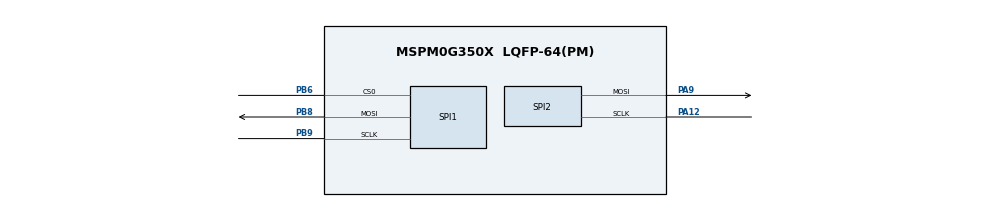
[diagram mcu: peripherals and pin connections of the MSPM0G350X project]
/**
 *
 * @cliArgs --device "MSPM0G350X" --part "Default" --package "LQFP-64(PM)" --product "mspm0_sdk@2.11.00.07"
 * @versions {"tool":"1.28.0+4696"}
 */

/**
 * Import the modules used in this configuration.
 */
const ADC12         = scripting.addModule("/ti/driverlib/ADC12", {}, false);
const ADC121        = ADC12.addInstance();
const ADC122        = ADC12.addInstance();
const Board         = scripting.addModule("/ti/driverlib/Board");
const GPIO          = scripting.addModule("/ti/driverlib/GPIO", {}, false);
const GPIO1         = GPIO.addInstance();
const GPIO2         = GPIO.addInstance();
const GPIO3         = GPIO.addInstance();
const SPI           = scripting.addModule("/ti/driverlib/SPI", {}, false);
const SPI1          = SPI.addInstance();
const SPI2          = SPI.addInstance();
const SYSCTL        = scripting.addModule("/ti/driverlib/SYSCTL");
const TIMER         = scripting.addModule("/ti/driverlib/TIMER", {}, false);
const TIMER1        = TIMER.addInstance();
const ProjectConfig = scripting.addModule("/ti/project_config/ProjectConfig");

/**
 * Write custom configuration values to the imported modules.
 */
const gate8  = system.clockTree["MFPCLKGATE"];
gate8.enable = true;

ADC121.$name                          = "SIGNAL_ADC_A";
ADC121.sampClkSrc                     = "DL_ADC12_CLOCK_ULPCLK";
ADC121.adcMem0chansel                 = "DL_ADC12_INPUT_CHAN_2";
ADC121.sampleTime0                    = "62.5ns";
ADC121.powerDownMode                  = "DL_ADC12_POWER_DOWN_MODE_MANUAL";
ADC121.trigSrc                        = "DL_ADC12_TRIG_SRC_EVENT";
ADC121.repeatMode                     = true;
ADC121.adcMem0trig                    = "DL_ADC12_TRIGGER_MODE_TRIGGER_NEXT";
ADC121.subChanID                      = 1;
ADC121.configureDMA                   = true;
ADC121.sampCnt                        = 1;
ADC121.enabledDMATriggers             = ["DL_ADC12_DMA_MEM0_RESULT_LOADED"];
ADC121.enabledInterrupts              = ["DL_ADC12_INTERRUPT_DMA_DONE"];
ADC121.peripheral.$assign             = "ADC0";
ADC121.peripheral.adcPin2.$assign     = "PA25";
ADC121.adcPin2Config.$name            = "ti_driverlib_gpio_GPIOPinGeneric0";
ADC121.DMA_CHANNEL.$name              = "SIGNAL_ADC_A_DMA";
ADC121.DMA_CHANNEL.addressMode        = "f2b";
ADC121.DMA_CHANNEL.srcLength          = "HALF_WORD";
ADC121.DMA_CHANNEL.dstLength          = "HALF_WORD";
ADC121.DMA_CHANNEL.peripheral.$assign = "DMA_CH0";

ADC122.$name                          = "SIGNAL_ADC_B";
ADC122.sampClkSrc                     = "DL_ADC12_CLOCK_ULPCLK";
ADC122.adcMem0chansel                 = "DL_ADC12_INPUT_CHAN_2";
ADC122.sampleTime0                    = "62.5ns";
ADC122.powerDownMode                  = "DL_ADC12_POWER_DOWN_MODE_MANUAL";
ADC122.trigSrc                        = "DL_ADC12_TRIG_SRC_EVENT";
ADC122.repeatMode                     = true;
ADC122.adcMem0trig                    = "DL_ADC12_TRIGGER_MODE_TRIGGER_NEXT";
ADC122.subChanID                      = 2;
ADC122.configureDMA                   = true;
ADC122.sampCnt                        = 1;
ADC122.enabledDMATriggers             = ["DL_ADC12_DMA_MEM0_RESULT_LOADED"];
ADC122.enabledInterrupts              = ["DL_ADC12_INTERRUPT_DMA_DONE"];
ADC122.peripheral.$assign             = "ADC1";
ADC122.peripheral.adcPin2.$assign     = "PA17";
ADC122.adcPin2Config.$name            = "ti_driverlib_gpio_GPIOPinGeneric1";
ADC122.DMA_CHANNEL.$name              = "SIGNAL_ADC_B_DMA";
ADC122.DMA_CHANNEL.addressMode        = "f2b";
ADC122.DMA_CHANNEL.srcLength          = "HALF_WORD";
ADC122.DMA_CHANNEL.dstLength          = "HALF_WORD";
ADC122.DMA_CHANNEL.peripheral.$assign = "DMA_CH1";

GPIO1.$name                          = "GPIO_TFT_CTRL";
GPIO1.associatedPins.create(2);
GPIO1.associatedPins[0].$name        = "TFT_DC";
GPIO1.associatedPins[0].assignedPort = "PORTB";
GPIO1.associatedPins[0].assignedPin  = "15";
GPIO1.associatedPins[1].$name        = "TFT_BLK";
GPIO1.associatedPins[1].initialValue = "SET";
GPIO1.associatedPins[1].assignedPort = "PORTB";
GPIO1.associatedPins[1].assignedPin  = "12";

GPIO2.$name                              = "GPIO_KEYPAD";
GPIO2.associatedPins.create(8);
GPIO2.associatedPins[0].$name            = "KEYPAD_R1";
GPIO2.associatedPins[0].initialValue     = "SET";
GPIO2.associatedPins[0].assignedPort     = "PORTB";
GPIO2.associatedPins[0].assignedPin      = "16";
GPIO2.associatedPins[1].$name            = "KEYPAD_R2";
GPIO2.associatedPins[1].initialValue     = "SET";
GPIO2.associatedPins[1].assignedPort     = "PORTB";
GPIO2.associatedPins[1].assignedPin      = "0";
GPIO2.associatedPins[2].$name            = "KEYPAD_R3";
GPIO2.associatedPins[2].initialValue     = "SET";
GPIO2.associatedPins[2].assignedPort     = "PORTB";
GPIO2.associatedPins[2].assignedPin      = "7";
GPIO2.associatedPins[3].$name            = "KEYPAD_R4";
GPIO2.associatedPins[3].initialValue     = "SET";
GPIO2.associatedPins[3].assignedPort     = "PORTB";
GPIO2.associatedPins[3].assignedPin      = "17";
GPIO2.associatedPins[4].$name            = "KEYPAD_C1";
GPIO2.associatedPins[4].direction        = "INPUT";
GPIO2.associatedPins[4].internalResistor = "PULL_UP";
GPIO2.associatedPins[4].assignedPort     = "PORTB";
GPIO2.associatedPins[4].assignedPin      = "18";
GPIO2.associatedPins[5].$name            = "KEYPAD_C2";
GPIO2.associatedPins[5].direction        = "INPUT";
GPIO2.associatedPins[5].internalResistor = "PULL_UP";
GPIO2.associatedPins[5].assignedPort     = "PORTB";
GPIO2.associatedPins[5].assignedPin      = "13";
GPIO2.associatedPins[6].$name            = "KEYPAD_C3";
GPIO2.associatedPins[6].direction        = "INPUT";
GPIO2.associatedPins[6].internalResistor = "PULL_UP";
GPIO2.associatedPins[6].assignedPort     = "PORTB";
GPIO2.associatedPins[6].assignedPin      = "20";
GPIO2.associatedPins[7].$name            = "KEYPAD_C4";
GPIO2.associatedPins[7].direction        = "INPUT";
GPIO2.associatedPins[7].internalResistor = "PULL_UP";
GPIO2.associatedPins[7].assignedPort     = "PORTB";
GPIO2.associatedPins[7].assignedPin      = "4";

GPIO3.$name                          = "GPIO_AD9833";
GPIO3.associatedPins.create(1);
GPIO3.associatedPins[0].$name        = "AD9833_FSYNC";
GPIO3.associatedPins[0].initialValue = "SET";
GPIO3.associatedPins[0].assignedPort = "PORTA";
GPIO3.associatedPins[0].assignedPin  = "8";

SPI1.$name                              = "SPI_TFT";
SPI1.peripheral.$assign                 = "SPI1";
SPI1.peripheral.sclkPin.$assign         = "PB9";
SPI1.peripheral.mosiPin.$assign         = "PB8";
SPI1.peripheral.cs0Pin.$assign          = "PB6";
SPI1.sclkPinConfig.$name                = "ti_driverlib_gpio_GPIOPinGeneric2";
SPI1.sclkPinConfig.direction            = scripting.forceWrite("OUTPUT");
SPI1.sclkPinConfig.onlyInternalResistor = scripting.forceWrite(false);
SPI1.sclkPinConfig.passedPeripheralType = scripting.forceWrite("Digital");
SPI1.sclkPinConfig.enableConfig         = true;
SPI1.mosiPinConfig.$name                = "ti_driverlib_gpio_GPIOPinGeneric3";
SPI1.mosiPinConfig.direction            = scripting.forceWrite("OUTPUT");
SPI1.mosiPinConfig.hideOutputInversion  = scripting.forceWrite(false);
SPI1.mosiPinConfig.onlyInternalResistor = scripting.forceWrite(false);
SPI1.mosiPinConfig.passedPeripheralType = scripting.forceWrite("Digital");
SPI1.mosiPinConfig.enableConfig         = true;
SPI1.misoPinConfig.$name                = "ti_driverlib_gpio_GPIOPinGeneric4";
SPI1.misoPinConfig.onlyInternalResistor = scripting.forceWrite(false);
SPI1.misoPinConfig.passedPeripheralType = scripting.forceWrite("Digital");
SPI1.cs0PinConfig.$name                 = "ti_driverlib_gpio_GPIOPinGeneric5";
SPI1.cs0PinConfig.direction             = scripting.forceWrite("OUTPUT");
SPI1.cs0PinConfig.hideOutputInversion   = scripting.forceWrite(false);
SPI1.cs0PinConfig.onlyInternalResistor  = scripting.forceWrite(false);
SPI1.cs0PinConfig.passedPeripheralType  = scripting.forceWrite("Digital");
SPI1.cs0PinConfig.enableConfig          = true;

/* AD9833 使用独立 SPI0：避免与必须保留的 ST7789 SPI1 共用 PB9/PB8。 */
SPI2.$name                              = "SPI_AD9833";
SPI2.frameFormat                        = "MOTO3";
SPI2.polarity                           = "1";
SPI2.phase                              = "0";
SPI2.direction                          = "PICO";
SPI2.targetBitRate                      = 4000000;
SPI2.peripheral.$assign                 = "SPI0";
SPI2.peripheral.sclkPin.$assign         = "PA12";
SPI2.peripheral.mosiPin.$assign         = "PA9";
SPI2.sclkPinConfig.$name                = "ti_driverlib_gpio_GPIOPinGeneric6";
SPI2.sclkPinConfig.direction            = scripting.forceWrite("OUTPUT");
SPI2.sclkPinConfig.onlyInternalResistor = scripting.forceWrite(false);
SPI2.sclkPinConfig.passedPeripheralType = scripting.forceWrite("Digital");
SPI2.sclkPinConfig.enableConfig         = true;
SPI2.mosiPinConfig.$name                = "ti_driverlib_gpio_GPIOPinGeneric7";
SPI2.mosiPinConfig.direction            = scripting.forceWrite("OUTPUT");
SPI2.mosiPinConfig.hideOutputInversion  = scripting.forceWrite(false);
SPI2.mosiPinConfig.onlyInternalResistor = scripting.forceWrite(false);
SPI2.mosiPinConfig.passedPeripheralType = scripting.forceWrite("Digital");
SPI2.mosiPinConfig.enableConfig         = true;

SYSCTL.forceDefaultClkConfig = true;
SYSCTL.clockTreeEn           = true;

TIMER1.$name                       = "SIGNAL_DUAL_ADC_TIMER";
TIMER1.timerPeriod                 = "2us";
TIMER1.timerMode                   = "PERIODIC";
TIMER1.event1PublisherChannel      = 1;
TIMER1.event1ControllerInterruptEn = ["ZERO_EVENT"];
TIMER1.event2PublisherChannel      = 2;
TIMER1.event2ControllerInterruptEn = ["ZERO_EVENT"];
TIMER1.peripheral.$assign          = "TIMG0";

ProjectConfig.genLibCMSIS = true;

/**
 * Pinmux solution for unlocked pins/peripherals. This ensures that minor changes to the automatic solver in a future
 * version of the tool will not impact the pinmux you originally saw.  These lines can be completely deleted in order to
 * re-solve from scratch.
 */
Board.peripheral.$suggestSolution            = "DEBUGSS";
Board.peripheral.swclkPin.$suggestSolution   = "PA20";
Board.peripheral.swdioPin.$suggestSolution   = "PA19";
GPIO1.associatedPins[0].pin.$suggestSolution = "PB15";
GPIO1.associatedPins[1].pin.$suggestSolution = "PB12";
GPIO2.associatedPins[0].pin.$suggestSolution = "PB16";
GPIO2.associatedPins[1].pin.$suggestSolution = "PB0";
GPIO2.associatedPins[2].pin.$suggestSolution = "PB7";
GPIO2.associatedPins[3].pin.$suggestSolution = "PB17";
GPIO2.associatedPins[4].pin.$suggestSolution = "PB18";
GPIO2.associatedPins[5].pin.$suggestSolution = "PB13";
GPIO2.associatedPins[6].pin.$suggestSolution = "PB20";
GPIO2.associatedPins[7].pin.$suggestSolution = "PB4";
GPIO3.associatedPins[0].pin.$suggestSolution = "PA8";
SPI1.peripheral.misoPin.$suggestSolution     = "PA16";
SPI2.peripheral.sclkPin.$suggestSolution     = "PA12";
SPI2.peripheral.mosiPin.$suggestSolution     = "PA9";
